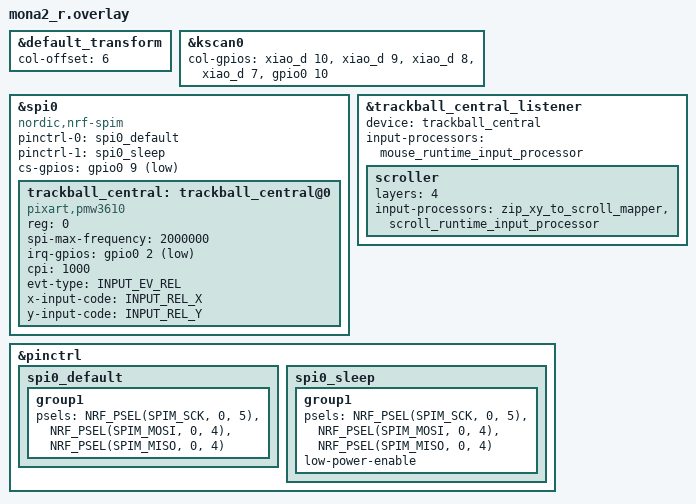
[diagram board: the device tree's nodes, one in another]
#include "mona2.dtsi"
#include <input/processors.dtsi>
#include <input/processors/runtime-input-processor.dtsi>
#include <behaviors/battery_history_request.dtsi>
#include <zephyr/dt-bindings/input/input-event-codes.h>

&default_transform {
    col-offset = <6>;
};

&kscan0 {
    col-gpios
        = <&xiao_d 10 GPIO_ACTIVE_HIGH>
        , <&xiao_d 9 GPIO_ACTIVE_HIGH> 
        , <&xiao_d 8 GPIO_ACTIVE_HIGH> 
        , <&xiao_d 7 GPIO_ACTIVE_HIGH> 
        , <&gpio0 10 GPIO_ACTIVE_HIGH>
        ;
};

/* --- SPI & Trackball Driver Configuration --- */
&spi0 {
    status = "okay";
    compatible = "nordic,nrf-spim";
    pinctrl-0 = <&spi0_default>;
    pinctrl-1 = <&spi0_sleep>;
    pinctrl-names = "default", "sleep";
    cs-gpios = <&gpio0 9 GPIO_ACTIVE_LOW>;

    trackball_central: trackball_central@0 {
        status = "okay";
        compatible = "pixart,pmw3610";
        reg = <0>;
        spi-max-frequency = <2000000>;
        irq-gpios = <&gpio0 2 (GPIO_ACTIVE_LOW | GPIO_PULL_UP)>;
        cpi = <1000>;
        
        /* * DYA Studio 対応のため、ドライバレベルでの固定設定(invert-x等)は削除します。
         * これらは DYA Studio の GUI からリアルタイムに設定・保存が可能になります。
         */
        evt-type = <INPUT_EV_REL>;
        x-input-code = <INPUT_REL_X>;
        y-input-code = <INPUT_REL_Y>;
    };
};

/* --- Input Listener & Runtime Processors --- */
&trackball_central_listener {
    status = "okay";
    device = <&trackball_central>;
    
    /* 通常時のマウス移動に DYA Studio の設定を適用 */
    input-processors = <&mouse_runtime_input_processor>;

    /* スクロールレイヤー (Layer 4) の設定 */
    scroller {
        layers = <4>;
        /* * zip_xy_transform や zip_scroll_scaler などの固定記述を削除し、
         * 全て DYA Studio 経由で調整できるように runtime-input-processor を配置します。
         */
        input-processors = <&zip_xy_to_scroll_mapper &scroll_runtime_input_processor>;
    };
};

/* --- Pinctrl (SPI) --- */
&pinctrl {
    spi0_default: spi0_default {
        group1 {
            psels = <NRF_PSEL(SPIM_SCK, 0, 5)>,
                    <NRF_PSEL(SPIM_MOSI, 0, 4)>,
                    <NRF_PSEL(SPIM_MISO, 0, 4)>;
        };
    };

    spi0_sleep: spi0_sleep {
        group1 {
            psels = <NRF_PSEL(SPIM_SCK, 0, 5)>,
                    <NRF_PSEL(SPIM_MOSI, 0, 4)>,
                    <NRF_PSEL(SPIM_MISO, 0, 4)>;
            low-power-enable;
        };
    };
};
